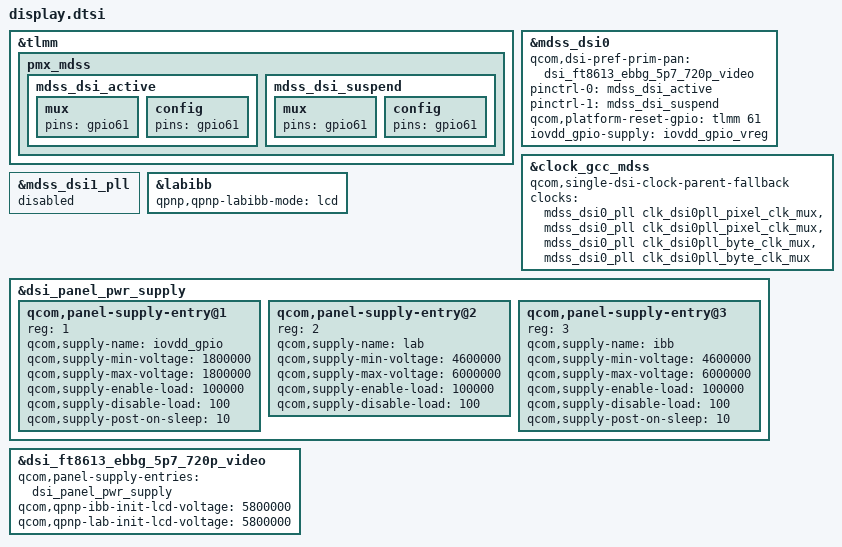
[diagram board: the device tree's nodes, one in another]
#include "../common/panel/dsi-panel-ft8613-ebbg-5p7-720p-video.dtsi"

&tlmm {
	pmx_mdss {
		mdss_dsi_active: mdss_dsi_active {
			mux {
				pins = "gpio61";
			};
			config {
				pins = "gpio61";
			};
		};
		mdss_dsi_suspend: mdss_dsi_suspend {
			mux {
				pins = "gpio61";
			};
			config {
				pins = "gpio61";
			};
		};
	};
};

&mdss_dsi0 {
	qcom,dsi-pref-prim-pan = <&dsi_ft8613_ebbg_5p7_720p_video>;
	pinctrl-0 = <&mdss_dsi_active>;
	pinctrl-1 = <&mdss_dsi_suspend>;
	qcom,platform-reset-gpio = <&tlmm 61 0>;
	iovdd_gpio-supply = <&iovdd_gpio_vreg>;
};

&clock_gcc_mdss {
	/*
	 * Rosy is a single-DSI board and keeps the second DSI PLL disabled.
	 * The 8953 MDSS GCC shim still requires all four external parent
	 * lookups before it registers the MDP/rotator vote clocks, so feed the
	 * unused secondary pixel/byte parents from DSI0 as inert stand-ins.
	 */
	qcom,single-dsi-clock-parent-fallback;
	clocks = <&mdss_dsi0_pll clk_dsi0pll_pixel_clk_mux>,
		<&mdss_dsi0_pll clk_dsi0pll_pixel_clk_mux>,
		<&mdss_dsi0_pll clk_dsi0pll_byte_clk_mux>,
		<&mdss_dsi0_pll clk_dsi0pll_byte_clk_mux>;
};

&mdss_dsi1_pll {
	status = "disabled";
};

&labibb {
	status = "ok";
	qpnp,qpnp-labibb-mode = "lcd";
};

&dsi_panel_pwr_supply {
	qcom,panel-supply-entry@1 {
		reg = <1>;
		qcom,supply-name = "iovdd_gpio";
		qcom,supply-min-voltage = <1800000>;
		qcom,supply-max-voltage = <1800000>;
		qcom,supply-enable-load = <100000>;
		qcom,supply-disable-load = <100>;
		qcom,supply-post-on-sleep = <10>;
	};
	qcom,panel-supply-entry@2 {
		reg = <2>;
		qcom,supply-name = "lab";
		qcom,supply-min-voltage = <4600000>;
		qcom,supply-max-voltage = <6000000>;
		qcom,supply-enable-load = <100000>;
		qcom,supply-disable-load = <100>;
	};

	qcom,panel-supply-entry@3 {
		reg = <3>;
		qcom,supply-name = "ibb";
		qcom,supply-min-voltage = <4600000>;
		qcom,supply-max-voltage = <6000000>;
		qcom,supply-enable-load = <100000>;
		qcom,supply-disable-load = <100>;
		qcom,supply-post-on-sleep = <10>;
	};
};

&dsi_ft8613_ebbg_5p7_720p_video {
	qcom,panel-supply-entries = <&dsi_panel_pwr_supply>;
	qcom,qpnp-ibb-init-lcd-voltage = <5800000>;
	qcom,qpnp-lab-init-lcd-voltage = <5800000>;
};
